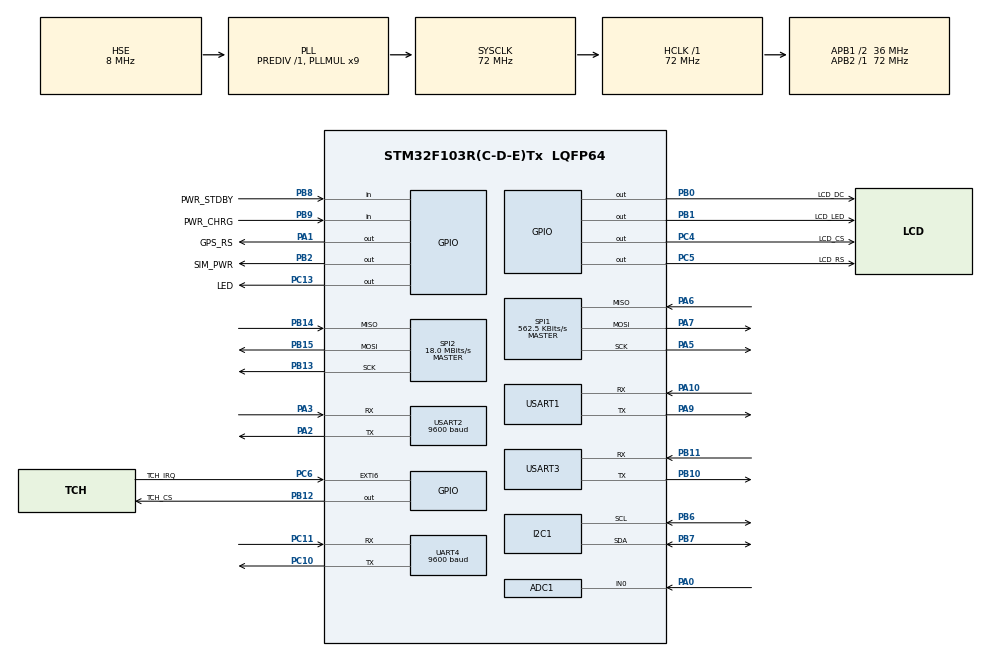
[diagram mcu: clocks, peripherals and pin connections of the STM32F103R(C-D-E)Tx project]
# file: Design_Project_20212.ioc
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ADC1.Channel-0\#ChannelRegularConversion=ADC_CHANNEL_0
ADC1.NbrOfConversionFlag=1
ADC1.Rank-0\#ChannelRegularConversion=1
ADC1.SamplingTime-0\#ChannelRegularConversion=ADC_SAMPLETIME_239CYCLES_5
ADC1.master=1
Dma.ADC1.0.Direction=DMA_PERIPH_TO_MEMORY
Dma.ADC1.0.Instance=DMA1_Channel1
Dma.ADC1.0.MemDataAlignment=DMA_MDATAALIGN_HALFWORD
Dma.ADC1.0.MemInc=DMA_MINC_ENABLE
Dma.ADC1.0.Mode=DMA_CIRCULAR
Dma.ADC1.0.PeriphDataAlignment=DMA_PDATAALIGN_HALFWORD
Dma.ADC1.0.PeriphInc=DMA_PINC_DISABLE
Dma.ADC1.0.Priority=DMA_PRIORITY_LOW
Dma.Request0=ADC1
FREERTOS.Tasks01=LCD_Task,24,200,LCDTASK,Default,NULL,Dynamic,NULL,NULL;SIM_Task,24,220,SIMTASK,Default,NULL,Dynamic,NULL,NULL;SEN_Task,24,200,SENSOR_Task,Default,NULL,Dynamic,NULL,NULL
FREERTOS.Timers01=LCD_Timer,LCD_Timer_Callback,osTimerPeriodic,Default,NULL,Dynamic,NULL;Touch_Timer,Touch_Timer_Callback,osTimerPeriodic,Default,NULL,Dynamic,NULL;LCD_Sleep,LCD_Sleep_Callback,osTimerOnce,Default,NULL,Dynamic,NULL
FREERTOS.configCHECK_FOR_STACK_OVERFLOW=0
FREERTOS.configGENERATE_RUN_TIME_STATS=0
FREERTOS.configMINIMAL_STACK_SIZE=100
FREERTOS.configTIMER_TASK_STACK_DEPTH=150
IWDG.Prescaler=IWDG_PRESCALER_128
IWDG.Reload=2500
Mcu.Family=STM32F1
Mcu.Name=STM32F103R(C-D-E)Tx
Mcu.Package=LQFP64
NVIC.DMA1_Channel1_IRQn=true\:5\:0\:false\:false\:true\:true\:false\:true\:true
NVIC.EXTI9_5_IRQn=true\:5\:0\:false\:false\:true\:false\:true\:true\:true
NVIC.PriorityGroup=NVIC_PRIORITYGROUP_4
NVIC.TIM1_UP_IRQn=true\:15\:0\:false\:false\:true\:false\:false\:true\:true
NVIC.TimeBase=TIM1_UP_IRQn
NVIC.TimeBaseIP=TIM1
NVIC.UART4_IRQn=true\:5\:0\:false\:false\:true\:true\:true\:true\:true
NVIC.USART1_IRQn=true\:5\:0\:false\:false\:true\:true\:true\:true\:true
NVIC.USART2_IRQn=true\:5\:0\:false\:false\:true\:true\:true\:true\:true
NVIC.USART3_IRQn=true\:5\:0\:false\:false\:true\:true\:true\:true\:true
PA0-WKUP.Signal=ADCx_IN0
PA1.GPIO_Label=GPS_RS
PA1.Signal=GPIO_Output
PA10.Mode=Asynchronous
PA10.Signal=USART1_RX
PA13.Mode=Serial_Wire
PA13.Signal=SYS_JTMS-SWDIO
PA14.Mode=Serial_Wire
PA14.Signal=SYS_JTCK-SWCLK
PA2.Mode=Asynchronous
PA2.Signal=USART2_TX
PA3.Mode=Asynchronous
PA3.Signal=USART2_RX
PA5.Mode=Full_Duplex_Master
PA5.Signal=SPI1_SCK
PA6.Mode=Full_Duplex_Master
PA6.Signal=SPI1_MISO
PA7.Mode=Full_Duplex_Master
PA7.Signal=SPI1_MOSI
PA9.Mode=Asynchronous
PA9.Signal=USART1_TX
PB0.GPIO_Label=LCD_DC
PB0.Signal=GPIO_Output
PB1.GPIO_Label=LCD_LED
PB1.Signal=GPIO_Output
PB10.Mode=Asynchronous
PB10.Signal=USART3_TX
PB11.Mode=Asynchronous
PB11.Signal=USART3_RX
PB12.GPIO_Label=TCH_CS
PB12.Signal=GPIO_Output
PB13.Mode=Full_Duplex_Master
PB13.Signal=SPI2_SCK
PB14.Mode=Full_Duplex_Master
PB14.Signal=SPI2_MISO
PB15.Mode=Full_Duplex_Master
PB15.Signal=SPI2_MOSI
PB2.GPIO_Label=SIM_PWR
PB2.Signal=GPIO_Output
PB6.Mode=I2C
PB6.Signal=I2C1_SCL
PB7.Mode=I2C
PB7.Signal=I2C1_SDA
PB8.GPIO_Label=PWR_STDBY
PB8.Signal=GPIO_Input
PB9.GPIO_Label=PWR_CHRG
PB9.Signal=GPIO_Input
PC10.Mode=Asynchronous
PC10.Signal=UART4_TX
PC11.Mode=Asynchronous
PC11.Signal=UART4_RX
PC13-TAMPER-RTC.GPIO_Label=LED
PC13-TAMPER-RTC.Signal=GPIO_Output
PC4.GPIO_Label=LCD_CS
PC4.Signal=GPIO_Output
PC5.GPIO_Label=LCD_RS
PC5.Signal=GPIO_Output
PC6.GPIO_Label=TCH_IRQ
PC6.GPIO_ModeDefaultEXTI=GPIO_MODE_IT_FALLING
PC6.GPIO_PuPd=GPIO_PULLUP
PC6.Signal=GPXTI6
PD0-OSC_IN.Mode=HSE-External-Oscillator
PD0-OSC_IN.Signal=RCC_OSC_IN
PD1-OSC_OUT.Mode=HSE-External-Oscillator
PD1-OSC_OUT.Signal=RCC_OSC_OUT
ProjectManager.HeapSize=0x200
ProjectManager.StackSize=0x400
ProjectManager.TargetToolchain=Makefile
RCC.ADCPresc=RCC_ADCPCLK2_DIV6
RCC.AHBFreq_Value=72000000
RCC.APB1CLKDivider=RCC_HCLK_DIV2
RCC.APB1Freq_Value=36000000
RCC.APB1TimFreq_Value=72000000
RCC.APB2Freq_Value=72000000
RCC.APB2TimFreq_Value=72000000
RCC.HCLKFreq_Value=72000000
RCC.PLLMUL=RCC_PLL_MUL9
RCC.PLLSourceVirtual=RCC_PLLSOURCE_HSE
RCC.SYSCLKFreq_VALUE=72000000
RCC.SYSCLKSource=RCC_SYSCLKSOURCE_PLLCLK
RCC.USBFreq_Value=72000000
SH.ADCx_IN0.0=ADC1_IN0,IN0
SPI1.BaudRatePrescaler=SPI_BAUDRATEPRESCALER_128
SPI1.CalculateBaudRate=562.5 KBits/s
SPI1.Direction=SPI_DIRECTION_2LINES
SPI1.Mode=SPI_MODE_MASTER
SPI1.VirtualType=VM_MASTER
SPI2.BaudRatePrescaler=SPI_BAUDRATEPRESCALER_2
SPI2.CalculateBaudRate=18.0 MBits/s
SPI2.Direction=SPI_DIRECTION_2LINES
SPI2.Mode=SPI_MODE_MASTER
SPI2.VirtualType=VM_MASTER
UART4.BaudRate=9600
UART4.VirtualMode=Asynchronous
USART1.VirtualMode=VM_ASYNC
USART2.BaudRate=9600
USART2.VirtualMode=VM_ASYNC
USART3.VirtualMode=VM_ASYNC
VP_FREERTOS_VS_CMSIS_V2.Mode=CMSIS_V2
VP_IWDG_VS_IWDG.Mode=IWDG_Activate
VP_SYS_VS_tim1.Mode=TIM1
board=custom

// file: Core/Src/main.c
/* USER CODE BEGIN Header */
/**
  ******************************************************************************
  * @file           : main.c
  * @brief          : Main program body
  ******************************************************************************
  * @attention
  *
  * Copyright (c) 2022 STMicroelectronics.
  * All rights reserved.
  *
  * This software is licensed under terms that can be found in the LICENSE file
  * in the root directory of this software component.
  * If no LICENSE file comes with this software, it is provided AS-IS.
  *
  ******************************************************************************
  */
/* USER CODE END Header */
#include "main.h"
#include "cmsis_os.h"
#include "adc.h"
#include "dma.h"
#include "i2c.h"
#include "iwdg.h"
#include "spi.h"
#include "usart.h"
#include "gpio.h"

void SystemClock_Config(void);
void MX_FREERTOS_Init(void);

int main(void)
{

  /* MCU Configuration--------------------------------------------------------*/

  /* Reset of all peripherals, Initializes the Flash interface and the Systick. */
  HAL_Init();

  /* Configure the system clock */
  SystemClock_Config();

  /* Initialize all configured peripherals */
  MX_GPIO_Init();
  MX_I2C1_Init();
  MX_SPI1_Init();
  MX_SPI2_Init();
  MX_UART4_Init();
  MX_USART1_UART_Init();
  MX_USART2_UART_Init();
  MX_DMA_Init();
  MX_ADC1_Init();
  MX_USART3_UART_Init();
  MX_IWDG_Init();

  /* Init scheduler */
  osKernelInitialize();  /* Call init function for freertos objects (in freertos.c) */
  MX_FREERTOS_Init();

  /* Start scheduler */
  osKernelStart();

  /* We should never get here as control is now taken by the scheduler */
  /* Infinite loop */
  while (1)
  {

  }
}

void SystemClock_Config(void)
{
  RCC_OscInitTypeDef RCC_OscInitStruct = {0};
  RCC_ClkInitTypeDef RCC_ClkInitStruct = {0};
  RCC_PeriphCLKInitTypeDef PeriphClkInit = {0};

  /** Initializes the RCC Oscillators according to the specified parameters
  * in the RCC_OscInitTypeDef structure.
  */
  RCC_OscInitStruct.OscillatorType = RCC_OSCILLATORTYPE_LSI|RCC_OSCILLATORTYPE_HSE;
  RCC_OscInitStruct.HSEState = RCC_HSE_ON;
  RCC_OscInitStruct.HSEPredivValue = RCC_HSE_PREDIV_DIV1;
  RCC_OscInitStruct.HSIState = RCC_HSI_ON;
  RCC_OscInitStruct.LSIState = RCC_LSI_ON;
  RCC_OscInitStruct.PLL.PLLState = RCC_PLL_ON;
  RCC_OscInitStruct.PLL.PLLSource = RCC_PLLSOURCE_HSE;
  RCC_OscInitStruct.PLL.PLLMUL = RCC_PLL_MUL9;
  if (HAL_RCC_OscConfig(&RCC_OscInitStruct) != HAL_OK)
  {
    Error_Handler();
  }

  /** Initializes the CPU, AHB and APB buses clocks
  */
  RCC_ClkInitStruct.ClockType = RCC_CLOCKTYPE_HCLK|RCC_CLOCKTYPE_SYSCLK
                              |RCC_CLOCKTYPE_PCLK1|RCC_CLOCKTYPE_PCLK2;
  RCC_ClkInitStruct.SYSCLKSource = RCC_SYSCLKSOURCE_PLLCLK;
  RCC_ClkInitStruct.AHBCLKDivider = RCC_SYSCLK_DIV1;
  RCC_ClkInitStruct.APB1CLKDivider = RCC_HCLK_DIV2;
  RCC_ClkInitStruct.APB2CLKDivider = RCC_HCLK_DIV1;

  if (HAL_RCC_ClockConfig(&RCC_ClkInitStruct, FLASH_LATENCY_2) != HAL_OK)
  {
    Error_Handler();
  }
  PeriphClkInit.PeriphClockSelection = RCC_PERIPHCLK_ADC;
  PeriphClkInit.AdcClockSelection = RCC_ADCPCLK2_DIV6;
  if (HAL_RCCEx_PeriphCLKConfig(&PeriphClkInit) != HAL_OK)
  {
    Error_Handler();
  }
}

void HAL_TIM_PeriodElapsedCallback(TIM_HandleTypeDef *htim)
{
  if (htim->Instance == TIM1) {
    HAL_IncTick();
  }
}

void Error_Handler(void)
{
  __disable_irq();
  while (1)
  {
  }
}

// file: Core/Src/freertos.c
/* USER CODE BEGIN Header */
/**
  ******************************************************************************
  * File Name          : freertos.c
  * Description        : Code for freertos applications
  ******************************************************************************
  * @attention
  *
  * Copyright (c) 2022 STMicroelectronics.
  * All rights reserved.
  *
  * This software is licensed under terms that can be found in the LICENSE file
  * in the root directory of this software component.
  * If no LICENSE file comes with this software, it is provided AS-IS.
  *
  ******************************************************************************
  */
/* USER CODE END Header */

#include "FreeRTOS.h"
#include "task.h"
#include "main.h"
#include "cmsis_os.h"

/* USER CODE BEGIN Includes */
#include "sim.h"
#include "l70.h"
#include "lcd.h"
#include "touch.h"
#include "mpu6050.h"
#include "ds1307.h"
#include "max30102.h"
#include "debug.h"
#include "stdlib.h"
#include "math.h"
#include "mqtt.h"
#include "DFPLAYER_MINI.h"
#include "timers.h"
#include "topic.h"

/* USER CODE END Includes */

/* USER CODE BEGIN PTD */
typedef enum
{
  STOP = 0,
  RUNNING = 1,
  PAUSE = 2
} Mode_t;

typedef struct
{
  uint16_t Voltage_12bits[1];
  float Voltage_V;
  float Voltage_Batt;
  uint8_t Perc_Batt;
  char cBatt[4];
} Battery_t;

/* USER CODE END PTD */

/* USER CODE BEGIN PD */

#define ADC_GAIN      (1.46527)
#define MAX_VOL       (4.22)
#define IR_THRESHOLD  (25000)

#define MAIN_PAGE     0
#define MP3_PAGE      1
#define DATA_PAGE_1   2
#define DATA_PAGE_2   3

#define ABS(x) ((x)<0 ? -(x) : (x))

/* USER CODE END PD */

/* USER CODE BEGIN Variables */
// extern IWDG_HandleTypeDef hiwdg;
extern I2C_HandleTypeDef hi2c1;
extern ADC_HandleTypeDef hadc1;
extern IWDG_HandleTypeDef hiwdg;

extern bool isNaize;

static bool isSystemOK = true;

static Mode_t DeviceState = STOP;
static MQTT_ST_t MQTT_Status = {
    .SIM_ST = SIM_SIMCARD_NOK,
    .MQTT_ST = MQTT_NOK
};
static bool isNewTime = false;
static bool isDeviceStateChange = false;

extern MQTT_t MQTT;
static char *GPSResponse;
static char latData[16] = "22.992335";
static char longData[16] = "105.886839";

static MPU6050_t MPU6050;
static RTC_t myRTC;
static max30102_t MAX30102 = {
  .Peak.maxPeak = 7,
  .Peak.minGap = 40
};
static uint8_t HeartRate = 0;
static uint32_t Step = 0;
static uint8_t TimeRun = 0;
static uint32_t IR_Value[250] = {0};
static uint8_t IR_Count = 0;
static uint32_t RD_Value[250] = {0};
static uint8_t RD_Count = 0;
static uint8_t count = 0;
static uint8_t tHR[4] = {0};
static bool isDataValid = false;

static Battery_t Batt = {
  .Perc_Batt = 0,
  .Voltage_12bits[0] = 0,
  .Voltage_Batt = 0.0,
  .Voltage_V = 0.0,
  .cBatt = {0}
};

static uint8_t CurrentPage = MAIN_PAGE;
static volatile bool isTouch = false;
static volatile bool isSleep = false;
const static myButton_t toPageLeft = {
  .pos_x = 30,
  .pos_y = 208,
  .color = ILI9341_LIGHTBLUE,
  .shape_r = 28
};
const static myButton_t toPageRight = {
  .pos_x = 290,
  .pos_y = 208,
  .color = ILI9341_LIGHTBLUE,
  .shape_r = 28
};
const static myButton_t bStart = {
  .pos_x = 130,
  .pos_y = 193,
  .color = ILI9341_GRAYBLUE,
  .shape_w = 60,
  .shape_h = 30
};
const static myButton_t bPause = {
  .pos_x = 90,
  .pos_y = 193,
  .color = ILI9341_GRAYBLUE,
  .shape_w = 60,
  .shape_h = 30
};
const static myButton_t bStop = {
  .pos_x = 170,
  .pos_y = 193,
  .color = ILI9341_GRAYBLUE,
  .shape_w = 60,
  .shape_h = 30
};
const static myButton_t bPlay = {
  .pos_x = 160,
  .pos_y = 120,
  .color = ILI9341_WHITE,
  .shape_r = 35
};
const static myButton_t bPrev = {
  .pos_x = 70,
  .pos_y = 120,
  .color = ILI9341_WHITE,
  .shape_r = 28
};
const static myButton_t bNext = {
  .pos_x = 250,
  .pos_y = 120,
  .color = ILI9341_WHITE,
  .shape_r = 28
};
const static myButton_t incVol = {
  .pos_x = 210,
  .pos_y = 190,
  .color = ILI9341_WHITE,
  .shape_r = 22
};
const static myButton_t decVol = {
  .pos_x = 110,
  .pos_y = 190,
  .color = ILI9341_WHITE,
  .shape_r = 22
};
static char DateFormat[22] = {0};
static char TimeFormat[8] = {0};
static char HRFormat[4] = {0};
static char StepFormat[7] = {0};
static char TimeRunFormat[5] = {0};
static bool isButtonChange = false;

static bool isMP3Playing = false;
static uint8_t MP3Volume = 1;

static uint8_t HRDataPlot[200] = {0};
static uint8_t HRDataIndex = 0;
static uint32_t StepDataPlot[200] = {0};
static uint8_t StepDataIndex = 0;

/* USER CODE END Variables */
/* Definitions for LCD_Task */
osThreadId_t LCD_TaskHandle;
const osThreadAttr_t LCD_Task_attributes = {
  .name = "LCD_Task",
  .stack_size = 512 * 4,
  .priority = (osPriority_t) osPriorityNormal,
};
/* Definitions for SIM_Task */
osThreadId_t SIM_TaskHandle;
const osThreadAttr_t SIM_Task_attributes = {
  .name = "SIM_Task",
  .stack_size = 512 * 4,
  .priority = (osPriority_t) osPriorityNormal,
};
/* Definitions for SEN_Task */
osThreadId_t SEN_TaskHandle;
const osThreadAttr_t SEN_Task_attributes = {
  .name = "SEN_Task",
  .stack_size = 512 * 4,
  .priority = (osPriority_t) osPriorityNormal,
};
/* Definitions for LCD_Timer */
osTimerId_t LCD_TimerHandle;
const osTimerAttr_t LCD_Timer_attributes = {
  .name = "LCD_Timer"
};
/* Definitions for Touch_Timer */
osTimerId_t Touch_TimerHandle;
const osTimerAttr_t Touch_Timer_attributes = {
  .name = "Touch_Timer"
};
/* Definitions for LCD_Sleep */
osTimerId_t LCD_SleepHandle;
const osTimerAttr_t LCD_Sleep_attributes = {
  .name = "LCD_Sleep"
};

/* USER CODE BEGIN FunctionPrototypes */

bool Connect_MQTT(void);
void updateParameter(uint8_t page);
void handleTouch(uint16_t x, uint16_t y, uint8_t page);
void updateButton(uint8_t page);

bool isPeak(int8_t* buffer, uint8_t size, uint8_t bandWith, int8_t minHeight, uint8_t numFlatPeak);

void Main_page(void);
void Mp3_page(void);
void Graph_page_1(void);
void Graph_page_2(void);

/* USER CODE END FunctionPrototypes */

void LCDTASK(void *argument);
void SIMTASK(void *argument);
void SENSOR_Task(void *argument);
void LCD_Timer_Callback(void *argument);
void Touch_Timer_Callback(void *argument);
void LCD_Sleep_Callback(void *argument);

void MX_FREERTOS_Init(void); /* (MISRA C 2004 rule 8.1) */

void MX_FREERTOS_Init(void) {

  /* Create the timer(s) */
  /* creation of LCD_Timer */
  LCD_TimerHandle = osTimerNew(LCD_Timer_Callback, osTimerPeriodic, NULL, &LCD_Timer_attributes);

  /* creation of Touch_Timer */
  Touch_TimerHandle = osTimerNew(Touch_Timer_Callback, osTimerPeriodic, NULL, &Touch_Timer_attributes);

  /* creation of LCD_Sleep */
  LCD_SleepHandle = osTimerNew(LCD_Sleep_Callback, osTimerOnce, NULL, &LCD_Sleep_attributes);

  /* Create the thread(s) */
  /* creation of LCD_Task */
  LCD_TaskHandle = osThreadNew(LCDTASK, NULL, &LCD_Task_attributes);

  /* creation of SIM_Task */
  SIM_TaskHandle = osThreadNew(SIMTASK, NULL, &SIM_Task_attributes);

  /* creation of SEN_Task */
  SEN_TaskHandle = osThreadNew(SENSOR_Task, NULL, &SEN_Task_attributes);

}

void LCDTASK(void *argument)
{
  /* USER CODE BEGIN LCDTASK */
  uint32_t TimeRefresh = HAL_GetTick();

  HAL_GPIO_WritePin(LED_GPIO_Port, LED_Pin, GPIO_PIN_RESET);

  ILI9341_Unselect();
  ILI9341_TouchUnselect();
  ILI9341_Init();
  isTouch = false;

  do
  {
    ds1307_get_current_date(&myRTC.Date);
    ds1307_get_current_time(&myRTC.Time);
  }
  while (myRTC.Time.minutes >= 60);

  ILI9341_FillRectangle(0, 0, 320, 25, ILI9341_BLACK);
  ILI9341_WriteString(10, 10, "SIM: ", Font_7x10, ILI9341_WHITE, ILI9341_BLACK);
  ILI9341_WriteString(80, 10, "GPRS: ", Font_7x10, ILI9341_WHITE, ILI9341_BLACK);
  ILI9341_WriteString(150, 10, "MQTT: ", Font_7x10, ILI9341_WHITE, ILI9341_BLACK);
  ILI9341_WriteString(225, 10, "Battery: ", Font_7x10, ILI9341_WHITE, ILI9341_BLACK);

  Main_page();

  uint16_t x = 0;
  uint16_t y = 0;

  TimeRefresh = HAL_GetTick();
  osTimerStart(LCD_TimerHandle, 5000);
  osTimerStart(Touch_TimerHandle, 50);
  osTimerStart(LCD_SleepHandle, 120000);
  if (isSystemOK == true)
  {
    HAL_IWDG_Refresh(&hiwdg);
  }
  // osThreadSuspend(LCD_TaskHandle);
  /* Infinite loop */
  for(;;)
  {
    if (isSystemOK == true)
    {
      HAL_IWDG_Refresh(&hiwdg);
    }
    osDelay(1);
    if ((HAL_GPIO_ReadPin(TCH_IRQ_GPIO_Port, TCH_IRQ_Pin) == GPIO_PIN_RESET) && (isTouch == true))
    {
      osDelay(100);
      if (HAL_GPIO_ReadPin(TCH_IRQ_GPIO_Port, TCH_IRQ_Pin) == GPIO_PIN_RESET)
      {
        x = 0;
        y = 0;
        while(ILI9341_TouchGetCoordinates(&y, &x) != true);
        y = 240 - y;
        x = 320 - x;
      }
      logPC("Touch Coordinate: (%i,%i)\n", x, y);
      xTimerReset(LCD_SleepHandle, 100);
      if (isSleep == true)
      {
        logPC("LCD awake!\n");
        updateParameter(CurrentPage);
        ILI9341_LCD_LED(true);
        // osTimerStart(LCD_TimerHandle, 5000);
        isSleep = false;
      }
      else
      {
        uint8_t Prev = CurrentPage;
        handleTouch(x, y, CurrentPage);
        if (Prev != CurrentPage)
        {
          if (CurrentPage == MAIN_PAGE)
          {
            Main_page();
          }
          else if (CurrentPage == MP3_PAGE)
          {
            Mp3_page();
          }
          else if (CurrentPage == DATA_PAGE_1)
          {
            Graph_page_1();
          }
          else if (CurrentPage == DATA_PAGE_2)
          {
            Graph_page_2();
          }
        }
        else
        {
          updateButton(CurrentPage);
        }
      }
      // ILI9341_DrawPixel(x, y, ILI9341_WHITE);
      osDelay(200);
    }
    else
    {
      updateParameter(CurrentPage);
    }
    isTouch = false;
    osThreadSuspend(LCD_TaskHandle);
  }
  /* USER CODE END LCDTASK */
}

void SIMTASK(void *argument)
{
  /* USER CODE BEGIN SIMTASK */
  SIM_Deinit();
  osThreadSuspend(SIM_TaskHandle);
  // osDelay(2000);
  uint32_t timeSIM = HAL_GetTick();
  uint32_t timePUB = HAL_GetTick();

  while ((SIM_Init() != true) && ((HAL_GetTick() - timeSIM) <= 20000))
  {
    osDelay(1000);
  }

  DF_Init(INIT_VOL);

  MQTT_Status.SIM_ST = SIM_SIMCARD_NOK;

  if (Connect_MQTT() == true)
  {
    osDelay(2000);
    // MQTT_Pub(STATUS_TOPIC, "1");
    // osDelay(1000);
    // MQTT_Sub(PING_TOPIC);
    osDelay(1000);
    MQTT_Sub(TIME_TOPIC);
  }

  osDelay(500);

  HAL_GPIO_WritePin(LED_GPIO_Port, LED_Pin, GPIO_PIN_SET);

  // l70_init();

  // DF_Sleep();

  // osTimerStart(MQTT_TimerHandle, 30000);
  timePUB = HAL_GetTick();
  uint32_t timeMP3 = HAL_GetTick();
  uint8_t ErrorTime = 0;

  /* Infinite loop */
  for(;;)
  {

    osDelay(100);
    // HAL_GPIO_TogglePin(LED_GPIO_Port, LED_Pin);
    if (((HAL_GetTick() - timeSIM) >= 90000) && (MQTT.mqttServer.connect == 1))
    {
      if (MQTT_PingReq() != true)
      {
        MQTT_Status.MQTT_ST = MQTT_NOK;
        MQTT.mqttServer.connect = 0;
        ErrorTime++;
      }
      else
      {
        MQTT.mqttServer.connect = 1;
        MQTT_Status.MQTT_ST = MQTT_OK;
        ErrorTime = 0;
      }
      timeSIM = HAL_GetTick();
    }
    if ((MQTT_Status.MQTT_ST != MQTT_OK) || (MQTT.mqttServer.connect == 0) || (MQTT_Status.SIM_ST != SIM_GPRS_OK))
    {
      if (Connect_MQTT() == true)
      {
        // osDelay(1000);
        // MQTT_Sub(PING_TOPIC);
        osDelay(1000);
        MQTT_Sub(TIME_TOPIC);
        ErrorTime = 0;
        timeSIM = HAL_GetTick();
      }
      else
      {ErrorTime++;}
    }
    if (MQTT.mqttReceive.newEvent == 1)
    {
      HAL_GPIO_TogglePin(LED_GPIO_Port, LED_Pin);
      logPC("MQTT Received from topic \"%s\", message is \"%s\"\n", MQTT.mqttReceive.topic, MQTT.mqttReceive.payload);
      MQTT.mqttReceive.newEvent = 0;
      SIM_clearRX();
      if (strstr(MQTT.mqttReceive.topic, "time") != NULL)
      {
        char* token = strtok(MQTT.mqttReceive.payload, ",");
        myRTC.Date.year = atoi(token);
        token = strtok(NULL, ",");
        myRTC.Date.month = atoi(token);
        token = strtok(NULL, ",");
        myRTC.Date.day = atoi(token);
        token = strtok(NULL, ",");
        myRTC.Date.date = atoi(token);
        token = strtok(NULL, ",");
        myRTC.Time.hours = atoi(token);
        token = strtok(NULL, ",");
        myRTC.Time.minutes = atoi(token);
        token = strtok(NULL, ",");
        myRTC.Time.seconds = atoi(token);
        isNewTime = true;
      }
      HAL_GPIO_TogglePin(LED_GPIO_Port, LED_Pin);
      timeSIM = HAL_GetTick();
    }
    if ((DeviceState == RUNNING) && ((HAL_GetTick() - timePUB) >= 10000) && (MQTT_Status.MQTT_ST == MQTT_OK))
    {
      char Upload[100] = {0};
      sprintf(Upload, "{\"HeartRate\":%03d,\"Step\":%06d,\"Period\":%03d,\"Lat\":%s,\"Lon\":%s}", HeartRate, Step, TimeRun, latData, longData);
      logPC("Data packet is %s\n", Upload);
      MQTT_Pub(DATA_TOPIC, Upload);
      timeSIM = HAL_GetTick();
      timePUB = HAL_GetTick();
    }
    else if ((DeviceState == STOP) || (DeviceState == PAUSE))
    {
      timePUB = HAL_GetTick();
    }
    if (DF_getState() == PAUSING && isMP3Playing == true)
    {
      osDelay(100);
      DF_Next();
      DF_Playback();
    }
    if (ErrorTime >= 5)
    {
      ErrorTime = 5;
      SIM_Deinit();
      osDelay(2000);
      SIM_Init();
      MQTT_Status.SIM_ST = SIM_SIMCARD_NOK;
      MQTT_Status.MQTT_ST = MQTT_NOK;
    }
    if ((isDeviceStateChange == true) && (MQTT_Status.MQTT_ST == MQTT_OK))
    {
      if (DeviceState == RUNNING)
      {MQTT_Pub(STATUS_TOPIC, "1");}
      else
      {MQTT_Pub(STATUS_TOPIC, "0");}
      osDelay(500);
      isDeviceStateChange = false;
    }
    if ((DF_getTotalSongs() == 0) && ((HAL_GetTick() - timeMP3) >= 10000))
    {
      DF_Init(INIT_VOL);
      osDelay(100);
      timeMP3 = HAL_GetTick();
    }
  }
  /* USER CODE END SIMTASK */
}

void SENSOR_Task(void *argument)
{
  /* USER CODE BEGIN SENSOR_Task */
  uint32_t lastTime = HAL_GetTick();
  uint32_t TimeHR = HAL_GetTick();
  uint32_t getTime = HAL_GetTick();
  uint32_t runTick = HAL_GetTick();

  Debug_Init();

  while (MPU6050_Init(&hi2c1) && ((HAL_GetTick() - lastTime) <= 10000))
  {
    osDelay(50);
  }
  if ((HAL_GetTick() - lastTime) > 10000)
  {
    // logPC("MPU6050 FAILED!\n");
    isSystemOK = false;
  }
  else
  {
    // logPC("MPU6050 OK\n");
  }

  osDelay(50);

  max30102_init(&MAX30102, &hi2c1);
  max30102_reset(&MAX30102);
  max30102_clear_fifo(&MAX30102);
  max30102_set_fifo_config(&MAX30102, max30102_smp_ave_32, 1, 5);

  // Sensor settings
  max30102_set_led_pulse_width(&MAX30102, max30102_pw_16_bit);
  max30102_set_adc_resolution(&MAX30102, max30102_adc_2048);
  max30102_set_sampling_rate(&MAX30102, max30102_sr_800);
  max30102_set_led_current_1(&MAX30102, 6.5);
  max30102_set_led_current_2(&MAX30102, 6.5);

  // Enter SpO2 mode
  max30102_set_mode(&MAX30102, max30102_spo2);
  max30102_set_a_full(&MAX30102, 0);

  // Initiate 1 temperature measurement
  max30102_set_die_temp_en(&MAX30102, 0);
  max30102_set_die_temp_rdy(&MAX30102, 0);

  uint8_t en_reg[2] = {0};
  max30102_read(&MAX30102, 0x00, en_reg, 1);
  osDelay(100);

  MAX30102.Peak.nPeak = 0;
  memset(MAX30102.Peak.peakLoc, '\0', sizeof(MAX30102.Peak.peakLoc));
  memset(tHR, '\0', sizeof(tHR));
  lastTime = HAL_GetTick();
  TimeHR = HAL_GetTick();
  getTime = HAL_GetTick();
  runTick = HAL_GetTick();

  int8_t AngleBuf[30] = {0};
  uint8_t fromLastPeak = 0;
  uint8_t startup = 0;

  // osDelay(500);
  /* Infinite loop */
  for(;;)
  {
    if ((HAL_GetTick() - getTime) >= 5000)
    {
      ds1307_get_current_date(&myRTC.Date);
      ds1307_get_current_time(&myRTC.Time);
      Batt.Voltage_V =  ((float) Batt.Voltage_12bits[0] / 4095) * 3.3;
      Batt.Voltage_Batt = Batt.Voltage_V * ADC_GAIN;
      Batt.Perc_Batt = (uint8_t) (Batt.Voltage_Batt * 100 / MAX_VOL);
      HAL_ADC_Start_DMA(&hadc1, (uint32_t*)Batt.Voltage_12bits, 1);
      if (myRTC.Date.year == 8)
      {
        MPU6050_Init(&hi2c1);
      }
      getTime = HAL_GetTick();
    }

    if (isNewTime == true)
    {
      ds1307_set_current_date(&myRTC.Date);
      ds1307_set_current_time(&myRTC.Time);
      isNewTime = false;
    }

    if ((HAL_GetTick() - lastTime) >= 30000)
    {
      char buf[5] = {0};
      // logPC("HELLO! Now is %02d/%02d/%02d %02d:%02d:%02d\n", myRTC.Date.date, myRTC.Date.month, myRTC.Date.year, myRTC.Time.hours, myRTC.Time.minutes, myRTC.Time.seconds);
      // logPC("ADC 12-bit value is %hu\n", Batt.Voltage_12bits[0]);
      // ftoa(Batt.Voltage_V, buf, 2);
      // logPC("ADC Voltage is %s\n", buf);
      // memset(buf, '\0', sizeof(buf));
      // ftoa0(Batt.Voltage_Batt, buf, 2);
      // logPC("Batt Voltage is %s\n", buf);
      // logPC("Percent Battery is %hd\n", Batt.Perc_Batt);
      lastTime = HAL_GetTick();
    }

    if ((HAL_GetTick() - TimeHR) >= 15000)
    {
      HeartRate = 0;
    }

    if (DeviceState == RUNNING)
    {
      if ((HAL_GetTick() - runTick) >= 60000)
      {
        TimeRun++;
        runTick = HAL_GetTick();
      }

      //--------------------------------------------------------------------- MPU -------------------------------------------------------------------

      MPU6050_Read_All(&hi2c1, &MPU6050);
      if ((MPU6050.Ax == 0.0) || (MPU6050.Ay == 0.0) || (MPU6050.Az == 0.0))
      {
        MPU6050_Init(&hi2c1);
        osDelay(100);
        MPU6050_Read_All(&hi2c1, &MPU6050);
      }

#if PLOT == 1
      // logPC("$%i %i %i;", (int)MPU6050.KalmanAngleX, (int)MPU6050.KalmanAngleY, (int)MPU6050.KalmanAngleZ);
#endif

      if (MPU6050.KalmanAngleZ != 0.0)
      {
        for (uint8_t i = 0; i < sizeof(AngleBuf)-1; i++)
        {
          AngleBuf[i] = AngleBuf[i+1];
        }
        AngleBuf[29] = (int8_t)MPU6050.KalmanAngleZ;
      }

      if (startup < 30)
      {
        startup++;
      }

      if ((fromLastPeak >= 7) && (startup >= 30))
      {
        if (isPeak(AngleBuf, sizeof(AngleBuf), 14, 15, 4) == true)
        {
          Step++;
          fromLastPeak = 0;
          if (osThreadGetState(LCD_TaskHandle) == osThreadBlocked)
          {
            osThreadResume(LCD_TaskHandle);
          }
        }
        else if (fromLastPeak < 250)
        {
          fromLastPeak++;
        }
      }
      else if (fromLastPeak < 250)
      {
        fromLastPeak++;
      }

      //--------------------------------------------------------------------- MAX -------------------------------------------------------------------

      max30102_read_fifo(&MAX30102);

      count = 0;
      while (MAX30102._ir_samples[count] != '\0')
      {
        IR_Value[IR_Count++] = MAX30102._ir_samples[count];
        RD_Value[RD_Count++] = MAX30102._red_samples[count];
        count++;
      }

      if (IR_Count >= 200)
      {
        isDataValid = true;
        for (uint8_t i = 0; ((i < 200) && (isDataValid == true)); i++)
        {
          // if (IR_Value[i] < IR_THRESHOLD*5)
          // {
          //   isDataValid = false;
          //   // logPC("Finger OFF\n");
          //   if (isNaize == true)
          //   {
          //     HeartRate += (int8_t) random_number(-5, 5);
          //     if (HeartRate >= 105)
          //     {HeartRate = 105;}
          //     if (HeartRate <= 75)
          //     {HeartRate = 75;}
          //     TimeHR = HAL_GetTick();
          //   }
          // }
          // else
          {
            // if ((i >= 2) && (i <= 197))
            // {
            //   IR_Value[i-1] = (IR_Value[i-2] + IR_Value[i-1] + IR_Value[i]) / 3;
            //   IR_Value[i] = (IR_Value[i-2] + IR_Value[i-1] + IR_Value[i] + IR_Value[i+1] + IR_Value[i+2]) / 5;
            //   IR_Value[i+1] = (IR_Value[i+2] + IR_Value[i+1] + IR_Value[i]) / 3;
            // }
#if PLOT == 1
            // char t[8] = {0};
            // t[0] = 0xAA;
            // t[1] = 0xBB;
            // t[2] = 0x04;
            // t[3] = (uint8_t)(((uint32_t)(IR_Value[i]/5) >> 24U) & 0xFF);
            // t[4] = (uint8_t)(((uint32_t)(IR_Value[i]/5) >> 16U) & 0xFF);
            // t[5] = (uint8_t)(((uint32_t)(IR_Value[i]/5) >> 8U) & 0xFF);
            // t[6] = (uint8_t)(((uint32_t)(IR_Value[i]/5) >> 0U) & 0xFF);
            // logPC("%s", t);
            logPC("%i,%i\n", IR_Value[i]/5, RD_Value[i]/5);
#endif
          }
        }
        if (isDataValid == true)
        {
          // logPC("Finger ON\n");
          MAX30102.Peak.nPeak = 0;
          for (uint8_t i = 0; i < 10; i++)
          {
            MAX30102.Peak.peakLoc[i] = '\0';
          }

          maxim_find_peaks(&MAX30102, IR_Value, (uint8_t)200);

          if (MAX30102.Peak.nPeak > 1)
          {
            uint32_t gap = 1;
            for (uint8_t i = 0; i < (MAX30102.Peak.nPeak-1); i++)
            {
              gap += (MAX30102.Peak.peakLoc[i+1] - MAX30102.Peak.peakLoc[i]);
            }

            uint8_t tHeartRate = (uint8_t)((60000.0 * MAX30102.Peak.nPeak) / (gap * (MAX30102.deltaTSample*2)));
            if ((tHeartRate >= 55) && (tHeartRate <= 140))
            {
              TimeHR = HAL_GetTick();
              tHR[0] = tHR[1];
              tHR[1] = tHR[2];
              tHR[2] = tHR[3];
              tHR[3] = tHeartRate;
              if (tHR[0] != '\0')
              {
                HeartRate = (uint8_t)((tHR[0] + tHR[1] + tHR[2] + tHR[3]) / 4);
                // logPC("Heart Rate: %d BPM\n", HeartRate);
              }
            }
          }
        }
        memset(IR_Value, '\0', 200*4);
        memcpy(IR_Value, IR_Value+200, 50*4);
        IR_Count -= 200;
      }
    }
    else
    {
      runTick = HAL_GetTick();
    }
    osDelay(50);
  }
  /* USER CODE END SENSOR_Task */
}

/* LCD_Timer_Callback function */
void LCD_Timer_Callback(void *argument)
{
  /* USER CODE BEGIN LCD_Timer_Callback */
  if (isSleep != true)
  {
    if (osThreadGetState(LCD_TaskHandle) == osThreadBlocked)
    {
      osThreadResume(LCD_TaskHandle);
    }
  }
  else
  {
    if (isSystemOK == true)
    {
      HAL_IWDG_Refresh(&hiwdg);
    }
  }

  if (DeviceState == RUNNING)
  {
    if (HRDataIndex >= 200)
    {
      for (uint8_t i = 0; i < 199; i++)
      {
        HRDataPlot[i] = HRDataPlot[i+1];
      }
      HRDataPlot[199] = HeartRate;
    }
    else
    {HRDataPlot[HRDataIndex++] = HeartRate;}

    if (StepDataIndex >= 200)
    {
      for (uint8_t i = 0; i < 199; i++)
      {
        StepDataPlot[i] = StepDataPlot[i+1];
      }
      StepDataPlot[199] = Step;
    }
    else
    {StepDataPlot[StepDataIndex++] = Step;}

    // if (isNaize == true)
    // {Step += (uint8_t) random_number(5, 20);}
  }
  /* USER CODE END LCD_Timer_Callback */
}

/* Touch_Timer_Callback function */
void Touch_Timer_Callback(void *argument)
{
  /* USER CODE BEGIN Touch_Timer_Callback */
  if ((isTouch == true) && (osThreadGetState(LCD_TaskHandle) == osThreadBlocked))
  {
    osThreadResume(LCD_TaskHandle);
  }
  /* USER CODE END Touch_Timer_Callback */
}

/* LCD_Sleep_Callback function */
void LCD_Sleep_Callback(void *argument)
{
  /* USER CODE BEGIN LCD_Sleep_Callback */
  logPC("LCD asleep!\n");
  ILI9341_LCD_LED(false);
  // osTimerStop(LCD_TimerHandle);
  isSleep = true;
  /* USER CODE END LCD_Sleep_Callback */
}

/* USER CODE BEGIN Application */
void HAL_UART_RxCpltCallback(UART_HandleTypeDef *huart)
{
  if (huart->Instance == USART3)
  {
    SIM_RXCallback();
  }
  if (huart->Instance == USART2)
  {
    l70_callback();
  }
  if (huart->Instance == USART1)
  {
    debug_callback();
  }
  if (huart->Instance == UART4)
  {
    DF_RX_Callback();
  }
}

void HAL_GPIO_EXTI_Callback(uint16_t GPIO_Pin)
{
  if ((GPIO_Pin == TCH_IRQ_Pin) && (isTouch != true))
  {
    isTouch = true;
    // osSemaphoreRelease(LCD_TouchHandle);
  }
}

//============================================================================================================================

bool Connect_MQTT(void)
{
  uint32_t TIMEOUT = HAL_GetTick();
  if (MQTT_Status.SIM_ST == SIM_SIMCARD_NOK)
  {
    TIMEOUT = HAL_GetTick();
    while ((SIM_checkSIMCard() != true) && ((HAL_GetTick() - TIMEOUT) <= 15000))
    {
      osDelay(1000);
    }

    if ((HAL_GetTick() - TIMEOUT) <= 10000)
    {
      MQTT_Status.SIM_ST = SIM_SIMCARD_OK;
      logPC("SIM OK\n");
      osDelay(1000);
    }
    else
    {
      logPC("SIM FAIL\n");
      return false;
    }
  }

  if ((MQTT_Status.SIM_ST == SIM_SIMCARD_OK) || (MQTT_Status.SIM_ST == SIM_GPRS_NOK))
  {
    if (SIM_startGPRS() == true)
    {
      logPC("GPRS OK\n");
      MQTT_Status.SIM_ST = SIM_GPRS_OK;
      osDelay(1000);
    }
    else
    {
      logPC("GPRS FAIL\n");
      MQTT_Status.SIM_ST = SIM_GPRS_NOK;
      return false;
    }

  }

  if (MQTT_Status.SIM_ST == SIM_GPRS_OK)
  {
    MQTT.mqttServer.host = "test.mosquitto.org";
    MQTT.mqttServer.port = 1883;
    MQTT.mqttClient.username = "";
    MQTT.mqttClient.clientID = "hmmm";
    MQTT.mqttClient.pass = "";
    MQTT.mqttClient.keepAliveInterval = 120;

    MQTT_Connect();

    osDelay(1000);

    if (MQTT.mqttServer.connect == 1)
    {
      logPC("MQTT OK\n");
      MQTT_Status.MQTT_ST = MQTT_OK;
      return true;
    }
    else
    {
      logPC("MQTT FAIL\n");
      MQTT_Status.MQTT_ST = MQTT_NOK;
      return false;
    }
  }

  return false;
}

void updateParameter(uint8_t page)
{
  switch (CurrentPage)
  {
    case MAIN_PAGE:
    {
      if ((MQTT_Status.SIM_ST == SIM_SIMCARD_OK) || (MQTT_Status.SIM_ST == SIM_GPRS_OK))
      {ILI9341_WriteString(45, 10, "OK ", Font_7x10, ILI9341_GREEN, ILI9341_BLACK);}
      else
      {ILI9341_WriteString(45, 10, "nOK", Font_7x10, ILI9341_RED, ILI9341_BLACK);}
      if (MQTT_Status.SIM_ST == SIM_GPRS_OK)
      {ILI9341_WriteString(122, 10, "OK ", Font_7x10, ILI9341_GREEN, ILI9341_BLACK);}
      else
      {ILI9341_WriteString(122, 10, "nOK", Font_7x10, ILI9341_RED, ILI9341_BLACK);}
      if ((MQTT_Status.MQTT_ST == MQTT_OK) && (MQTT_Status.SIM_ST == SIM_GPRS_OK))
      {ILI9341_WriteString(192, 10, "OK ", Font_7x10, ILI9341_GREEN, ILI9341_BLACK);}
      else
      {ILI9341_WriteString(192, 10, "nOK", Font_7x10, ILI9341_RED, ILI9341_BLACK);}

      ILI9341_WriteString(225, 10, "Battery: ", Font_7x10, ILI9341_WHITE, ILI9341_BLACK);
      intToStr(Batt.Perc_Batt, Batt.cBatt, 3);
      ILI9341_WriteString(288, 10, Batt.cBatt, Font_7x10, ILI9341_YELLOW, ILI9341_BLACK);
      ILI9341_WriteString(309, 10, "%", Font_7x10, ILI9341_WHITE, ILI9341_BLACK);

      memset(DateFormat, '\0', sizeof(DateFormat));
      sprintf(DateFormat, "~~~ %02d/%02d/%4d ~~~\0", myRTC.Date.date, myRTC.Date.month, myRTC.Date.year+2000);
      ILI9341_WriteString(97, 30, DateFormat, Font_7x10, ILI9341_WHITE, ILI9341_BLACK);

      memset(TimeFormat, '\0', sizeof(TimeFormat));
      sprintf(TimeFormat, "%02d:%02d\0", myRTC.Time.hours, myRTC.Time.minutes);
      ILI9341_WriteString(133, 45, TimeFormat, Font_11x18, ILI9341_CYAN, ILI9341_BLACK);

      memset(HRFormat, '\0', sizeof(HRFormat));
      sprintf(HRFormat, "%03d", HeartRate);
      ILI9341_WriteString(37, 95, HRFormat, Font_11x18, ILI9341_RED, ILI9341_BLACK);

      memset(StepFormat, '\0', sizeof(StepFormat));
      sprintf(StepFormat, "%06ld", Step);
      ILI9341_WriteString(177, 95, StepFormat, Font_11x18, ILI9341_ORANGE, ILI9341_BLACK);

      memset(TimeRunFormat, '\0', sizeof(TimeRunFormat));
      sprintf(TimeRunFormat, "%03d", TimeRun);
      ILI9341_WriteString(36, 150, TimeRunFormat, Font_11x18, ILI9341_PINK, ILI9341_BLACK);

      ILI9341_WriteString(229, 147, latData, Font_7x10, ILI9341_GREEN, ILI9341_BLACK);
      ILI9341_WriteString(222, 160, longData, Font_7x10, ILI9341_GREEN, ILI9341_BLACK);

      break;
    }
    case MP3_PAGE:
    {
      if ((MQTT_Status.SIM_ST == SIM_SIMCARD_OK) || (MQTT_Status.SIM_ST == SIM_GPRS_OK))
      {ILI9341_WriteString(45, 10, "OK ", Font_7x10, ILI9341_GREEN, ILI9341_BLACK);}
      else
      {ILI9341_WriteString(45, 10, "nOK", Font_7x10, ILI9341_RED, ILI9341_BLACK);}
      if (MQTT_Status.SIM_ST == SIM_GPRS_OK)
      {ILI9341_WriteString(122, 10, "OK ", Font_7x10, ILI9341_GREEN, ILI9341_BLACK);}
      else
      {ILI9341_WriteString(122, 10, "nOK", Font_7x10, ILI9341_RED, ILI9341_BLACK);}
      if ((MQTT_Status.MQTT_ST == MQTT_OK) && (MQTT_Status.SIM_ST == SIM_GPRS_OK))
      {ILI9341_WriteString(192, 10, "OK ", Font_7x10, ILI9341_GREEN, ILI9341_BLACK);}
      else
      {ILI9341_WriteString(192, 10, "nOK", Font_7x10, ILI9341_RED, ILI9341_BLACK);}

      ILI9341_WriteString(225, 10, "Battery: ", Font_7x10, ILI9341_WHITE, ILI9341_BLACK);
      intToStr(Batt.Perc_Batt, Batt.cBatt, 3);
      ILI9341_WriteString(288, 10, Batt.cBatt, Font_7x10, ILI9341_YELLOW, ILI9341_BLACK);
      ILI9341_WriteString(309, 10, "%", Font_7x10, ILI9341_WHITE, ILI9341_BLACK);
      // ILI9341_WriteString(200, 50, "VOLUME: ", Font_11x18, ILI9341_YELLOW, ILI9341_BLACK);
      char temp[5] = {0};
      intToStr0(MP3Volume, temp, 2);
      ILI9341_WriteString(288, 50, temp, Font_11x18, ILI9341_YELLOW, ILI9341_BLACK);

      // ILI9341_WriteString(10, 50, "TRACK: ", Font_11x18, ILI9341_CYAN, ILI9341_BLACK);
      memset(temp, '\0', sizeof(temp));
      intToStr0(DF_getCurrentSongNumber(), temp, 4);
      ILI9341_WriteString(87, 50, temp, Font_11x18, ILI9341_CYAN, ILI9341_BLACK);
      // ILI9341_WriteString(131, 50, "/", Font_11x18, ILI9341_CYAN, ILI9341_BLACK);
      memset(temp, '\0', sizeof(temp));
      intToStr0(DF_getTotalSongs(), temp, 4);
      ILI9341_WriteString(142, 50, temp, Font_11x18, ILI9341_CYAN, ILI9341_BLACK);
      break;
    }
    case DATA_PAGE_1:
    {
      if ((MQTT_Status.SIM_ST == SIM_SIMCARD_OK) || (MQTT_Status.SIM_ST == SIM_GPRS_OK))
      {ILI9341_WriteString(45, 10, "OK ", Font_7x10, ILI9341_GREEN, ILI9341_BLACK);}
      else
      {ILI9341_WriteString(45, 10, "nOK", Font_7x10, ILI9341_RED, ILI9341_BLACK);}
      if (MQTT_Status.SIM_ST == SIM_GPRS_OK)
      {ILI9341_WriteString(122, 10, "OK ", Font_7x10, ILI9341_GREEN, ILI9341_BLACK);}
      else
      {ILI9341_WriteString(122, 10, "nOK", Font_7x10, ILI9341_RED, ILI9341_BLACK);}
      if ((MQTT_Status.MQTT_ST == MQTT_OK) && (MQTT_Status.SIM_ST == SIM_GPRS_OK))
      {ILI9341_WriteString(192, 10, "OK ", Font_7x10, ILI9341_GREEN, ILI9341_BLACK);}
      else
      {ILI9341_WriteString(192, 10, "nOK", Font_7x10, ILI9341_RED, ILI9341_BLACK);}

      ILI9341_WriteString(225, 10, "Battery: ", Font_7x10, ILI9341_WHITE, ILI9341_BLACK);
      intToStr(Batt.Perc_Batt, Batt.cBatt, 3);
      ILI9341_WriteString(288, 10, Batt.cBatt, Font_7x10, ILI9341_YELLOW, ILI9341_BLACK);
      ILI9341_WriteString(309, 10, "%", Font_7x10, ILI9341_WHITE, ILI9341_BLACK);
      break;
    }
    case DATA_PAGE_2:
    {
      if ((MQTT_Status.SIM_ST == SIM_SIMCARD_OK) || (MQTT_Status.SIM_ST == SIM_GPRS_OK))
      {ILI9341_WriteString(45, 10, "OK ", Font_7x10, ILI9341_GREEN, ILI9341_BLACK);}
      else
      {ILI9341_WriteString(45, 10, "nOK", Font_7x10, ILI9341_RED, ILI9341_BLACK);}
      if (MQTT_Status.SIM_ST == SIM_GPRS_OK)
      {ILI9341_WriteString(122, 10, "OK ", Font_7x10, ILI9341_GREEN, ILI9341_BLACK);}
      else
      {ILI9341_WriteString(122, 10, "nOK", Font_7x10, ILI9341_RED, ILI9341_BLACK);}
      if ((MQTT_Status.MQTT_ST == MQTT_OK) && (MQTT_Status.SIM_ST == SIM_GPRS_OK))
      {ILI9341_WriteString(192, 10, "OK ", Font_7x10, ILI9341_GREEN, ILI9341_BLACK);}
      else
      {ILI9341_WriteString(192, 10, "nOK", Font_7x10, ILI9341_RED, ILI9341_BLACK);}

      ILI9341_WriteString(225, 10, "Battery: ", Font_7x10, ILI9341_WHITE, ILI9341_BLACK);
      intToStr(Batt.Perc_Batt, Batt.cBatt, 3);
      ILI9341_WriteString(288, 10, Batt.cBatt, Font_7x10, ILI9341_YELLOW, ILI9341_BLACK);
      ILI9341_WriteString(309, 10, "%", Font_7x10, ILI9341_WHITE, ILI9341_BLACK);
      break;
    }
    default:
    {
      break;
    }
  }
}

void updateButton(uint8_t page)
{
  if (page == MAIN_PAGE)
  {
    if (isButtonChange == true)
    {
      ILI9341_FillRectangle(bPause.pos_x, bPause.pos_y, 140, 30, ILI9341_BLACK);

      if (DeviceState == STOP)
      {
        ILI9341_FillRectangle(bStart.pos_x, bStart.pos_y, bStart.shape_w, bStart.shape_h, bStart.color);
        ILI9341_WriteString(bStart.pos_x+3, bStart.pos_y+6, "START", Font_11x18, ILI9341_WHITE, bStart.color);
      }
      else if (DeviceState == RUNNING)
      {
        ILI9341_FillRectangle(bPause.pos_x, bPause.pos_y, bPause.shape_w, bPause.shape_h, bPause.color);
        ILI9341_WriteString(bPause.pos_x+3, bPause.pos_y+6, "PAUSE", Font_11x18, ILI9341_WHITE, bPause.color);
        ILI9341_FillRectangle(bStop.pos_x, bStop.pos_y, bStop.shape_w, bStop.shape_h, bStop.color);
        ILI9341_WriteString(bStop.pos_x+8, bStop.pos_y+6, "STOP", Font_11x18, ILI9341_WHITE, bStop.color);
      }
      else
      {
        ILI9341_FillRectangle(bPause.pos_x, bPause.pos_y, bPause.shape_w, bPause.shape_h, bPause.color);
        ILI9341_WriteString(bPause.pos_x+3, bPause.pos_y+6, "START", Font_11x18, ILI9341_WHITE, bPause.color);
        ILI9341_FillRectangle(bStop.pos_x, bStop.pos_y, bStop.shape_w, bStop.shape_h, bStop.color);
        ILI9341_WriteString(bStop.pos_x+8, bStop.pos_y+6, "STOP", Font_11x18, ILI9341_WHITE, bStop.color);
      }
      isButtonChange = false;
    }
  }
  else if (page == MP3_PAGE)
  {
    if (isButtonChange == true)
    {
      ILI9341_FillCircle(bPlay.pos_x, bPlay.pos_y, bPlay.shape_r, bPlay.color);
      if (isMP3Playing == false)
      {ILI9341_FillTriangle(bPlay.pos_x+20, bPlay.pos_y, bPlay.pos_x-10, bPlay.pos_y+18, bPlay.pos_x-10, bPlay.pos_y-18, ILI9341_ORANGE);}
      else
      {
        ILI9341_FillRectangle(bPlay.pos_x-5-bPlay.shape_r+20, bPlay.pos_y-bPlay.shape_r/2, bPlay.shape_r-20, bPlay.shape_r, ILI9341_RED);
        ILI9341_FillRectangle(bPlay.pos_x+5, bPlay.pos_y-bPlay.shape_r/2, bPlay.shape_r-20, bPlay.shape_r, ILI9341_RED);
      }
      isButtonChange = false;
    }
    // ILI9341_WriteString(200, 50, "VOLUME: ", Font_11x18, ILI9341_YELLOW, ILI9341_BLACK);
    char temp[5] = {0};
    intToStr0(MP3Volume, temp, 2);
    ILI9341_WriteString(288, 50, temp, Font_11x18, ILI9341_YELLOW, ILI9341_BLACK);

    // ILI9341_WriteString(10, 50, "TRACK: ", Font_11x18, ILI9341_CYAN, ILI9341_BLACK);
    memset(temp, '\0', sizeof(temp));
    intToStr0(DF_getCurrentSongNumber(), temp, 4);
    ILI9341_WriteString(87, 50, temp, Font_11x18, ILI9341_CYAN, ILI9341_BLACK);
    // ILI9341_WriteString(131, 50, "/", Font_11x18, ILI9341_CYAN, ILI9341_BLACK);
    // memset(temp, '\0', sizeof(temp));
    // intToStr0(DF_getTotalSongs(), temp, 4);
    // ILI9341_WriteString(142, 50, temp, Font_11x18, ILI9341_CYAN, ILI9341_BLACK);
  }
}

void handleTouch(uint16_t x, uint16_t y, uint8_t page)
{
  switch (page)
  {
    case MAIN_PAGE:
    {
      if (ILI9341_checkButton(x, y, &toPageLeft))
      {
        CurrentPage = MP3_PAGE;
      }
      else if (ILI9341_checkButton(x, y, &toPageRight))
      {
        CurrentPage = DATA_PAGE_1;
      }
      else if (DeviceState == STOP)
      {
        if (ILI9341_checkButton(x, y, &bStart))
        {
          DeviceState = RUNNING;
          max30102_clear_fifo(&MAX30102);
          isButtonChange = true;
          isDeviceStateChange = true;
          memset(HRDataPlot, '\0', sizeof(HRDataPlot));
          memset(StepDataPlot, '\0', sizeof(StepDataPlot));
          HRDataIndex = 0;
          StepDataIndex = 0;
        }
      }
      else if (DeviceState == RUNNING)
      {
        if (ILI9341_checkButton(x, y, &bPause))
        {
          DeviceState = PAUSE;
          isButtonChange = true;
          isDeviceStateChange = true;
        }
        else if (ILI9341_checkButton(x, y, &bStop))
        {
          DeviceState = STOP;
          isButtonChange = true;
          isDeviceStateChange = true;
        }
      }
      else
      {
        if (ILI9341_checkButton(x, y, &bPause))
        {
          DeviceState = RUNNING;
          max30102_clear_fifo(&MAX30102);
          isButtonChange = true;
          isDeviceStateChange = true;
        }
        else if (ILI9341_checkButton(x, y, &bStop))
        {
          DeviceState = STOP;
          isButtonChange = true;
          isDeviceStateChange = true;
        }
      }
      break;
    }
    case MP3_PAGE:
    {
      if (ILI9341_checkButton(x, y, &toPageLeft))
      {
        CurrentPage = DATA_PAGE_2;
      }
      else if (ILI9341_checkButton(x, y, &toPageRight))
      {
        CurrentPage = MAIN_PAGE;
      }
      else if (ILI9341_checkButton(x, y, &bPlay))
      {
        isMP3Playing = !isMP3Playing;
        if (isMP3Playing == true)
        {DF_Playback();}
        else
        {DF_Pause();}
        isButtonChange = true;
      }
      else if (ILI9341_checkButton(x, y, &bPrev))
      {
        DF_Previous();
        if (isMP3Playing == false)
        {isButtonChange = true;}
        isMP3Playing = true;
        if (DF_getCurrentSongNumber() != 1)
        {DF_setCurrentSongNumber(DF_getCurrentSongNumber()-1);}
        else
        {DF_setCurrentSongNumber(DF_getTotalSongs());}
      }
      else if (ILI9341_checkButton(x, y, &bNext))
      {
        DF_Next();
        if (isMP3Playing == false)
        {isButtonChange = true;}
        isMP3Playing = true;
        if (DF_getCurrentSongNumber() != DF_getTotalSongs())
        {DF_setCurrentSongNumber(DF_getCurrentSongNumber()+1);}
        else
        {DF_setCurrentSongNumber(1);}
      }
      else if (ILI9341_checkButton(x, y, &incVol))
      {
        if (MP3Volume < 9)
        {MP3Volume++;}
        DF_SetVol(MP3Volume);
      }
      else if (ILI9341_checkButton(x, y, &decVol))
      {
        if (MP3Volume > 0)
        {MP3Volume--;}
        DF_SetVol(MP3Volume);
      }
      break;
    }
    case DATA_PAGE_2:
    {
      if (ILI9341_checkButton(x, y, &toPageLeft))
      {
        CurrentPage = DATA_PAGE_1;
      }
      else if (ILI9341_checkButton(x, y, &toPageRight))
      {
        CurrentPage = MP3_PAGE;
      }
      break;
    }
    case DATA_PAGE_1:
    {
      if (ILI9341_checkButton(x, y, &toPageLeft))
      {
        CurrentPage = MAIN_PAGE;
      }
      else if (ILI9341_checkButton(x, y, &toPageRight))
      {
        CurrentPage = DATA_PAGE_2;
      }
      break;
    }
    default:
    {
      break;
    }
  }
}

void Main_page(void)
{
  //========================================== CLEAR ================================================

  // ILI9341_FillScreen(ILI9341_BLACK);
  ILI9341_FillRectangle(0, 25, 320, 240, ILI9341_BLACK);

  //========================================= HEADER ========================================================

  if ((MQTT_Status.SIM_ST == SIM_SIMCARD_OK) || (MQTT_Status.SIM_ST == SIM_GPRS_OK))
  {ILI9341_WriteString(45, 10, "OK ", Font_7x10, ILI9341_GREEN, ILI9341_BLACK);}
  else
  {ILI9341_WriteString(45, 10, "nOK", Font_7x10, ILI9341_RED, ILI9341_BLACK);}
  if (MQTT_Status.SIM_ST == SIM_GPRS_OK)
  {ILI9341_WriteString(122, 10, "OK ", Font_7x10, ILI9341_GREEN, ILI9341_BLACK);}
  else
  {ILI9341_WriteString(122, 10, "nOK", Font_7x10, ILI9341_RED, ILI9341_BLACK);}
  if ((MQTT_Status.MQTT_ST == MQTT_OK) && (MQTT_Status.SIM_ST == SIM_GPRS_OK))
  {ILI9341_WriteString(192, 10, "OK ", Font_7x10, ILI9341_GREEN, ILI9341_BLACK);}
  else
  {ILI9341_WriteString(192, 10, "nOK", Font_7x10, ILI9341_RED, ILI9341_BLACK);}

  intToStr(Batt.Perc_Batt, Batt.cBatt, 3);
  ILI9341_WriteString(288, 10, Batt.cBatt, Font_7x10, ILI9341_YELLOW, ILI9341_BLACK);
  ILI9341_WriteString(309, 10, "%", Font_7x10, ILI9341_WHITE, ILI9341_BLACK);

  //============================================ DATE TIME =========================================

  memset(DateFormat, '\0', sizeof(DateFormat));
  sprintf(DateFormat, "~~~ %02d/%02d/%4d ~~~", myRTC.Date.date, myRTC.Date.month, myRTC.Date.year+2000);
  ILI9341_WriteString(97, 30, DateFormat, Font_7x10, ILI9341_WHITE, ILI9341_BLACK);

  memset(TimeFormat, '\0', sizeof(TimeFormat));
  sprintf(TimeFormat, "%02d:%02d", myRTC.Time.hours, myRTC.Time.minutes);
  ILI9341_WriteString(133, 45, TimeFormat, Font_11x18, ILI9341_CYAN, ILI9341_BLACK);

  //============================================ PARAMETERs =========================================

  ILI9341_WriteString(25, 70, "Heart Rate", Font_11x18, ILI9341_RED, ILI9341_BLACK);
  memset(HRFormat, '\0', sizeof(HRFormat));
  sprintf(HRFormat, "%03d", HeartRate);
  ILI9341_WriteString(37, 95, HRFormat, Font_11x18, ILI9341_RED, ILI9341_BLACK);
  ILI9341_WriteString(70, 95, " BPM", Font_11x18, ILI9341_RED, ILI9341_BLACK);

  ILI9341_WriteString(218, 70, "Step", Font_11x18, ILI9341_ORANGE, ILI9341_BLACK);
  memset(StepFormat, '\0', sizeof(StepFormat));
  sprintf(StepFormat, "%06ld", Step);
  ILI9341_WriteString(177, 95, StepFormat, Font_11x18, ILI9341_ORANGE, ILI9341_BLACK);
  ILI9341_WriteString(243, 95, " steps", Font_11x18, ILI9341_ORANGE, ILI9341_BLACK);

  ILI9341_WriteString(36, 125, "Run Time", Font_11x18, ILI9341_PINK, ILI9341_BLACK);
  memset(TimeRunFormat, '\0', sizeof(TimeRunFormat));
  sprintf(TimeRunFormat, "%03d", TimeRun);
  ILI9341_WriteString(36, 150, TimeRunFormat, Font_11x18, ILI9341_PINK, ILI9341_BLACK);
  ILI9341_WriteString(69, 150, " mins", Font_11x18, ILI9341_PINK, ILI9341_BLACK);

  ILI9341_WriteString(179, 125, "Coordinates", Font_11x18, ILI9341_GREEN, ILI9341_BLACK);
  ILI9341_WriteString(187, 147, "Lat: ", Font_7x10, ILI9341_GREEN, ILI9341_BLACK);
  ILI9341_WriteString(229, 147, latData, Font_7x10, ILI9341_GREEN, ILI9341_BLACK);
  ILI9341_WriteString(187, 160, "Lon: ", Font_7x10, ILI9341_GREEN, ILI9341_BLACK);
  ILI9341_WriteString(222, 160, longData, Font_7x10, ILI9341_GREEN, ILI9341_BLACK);

  //======================================= BUTTONs ================================================

  ILI9341_FillRectangle(bPause.pos_x, bPause.pos_y, 140, 30, ILI9341_BLACK);

  if (DeviceState == STOP)
  {
    ILI9341_FillRectangle(bStart.pos_x, bStart.pos_y, bStart.shape_w, bStart.shape_h, bStart.color);
    ILI9341_WriteString(bStart.pos_x+3, bStart.pos_y+6, "START", Font_11x18, ILI9341_WHITE, bStart.color);
  }
  else if (DeviceState == RUNNING)
  {
    ILI9341_FillRectangle(bPause.pos_x, bPause.pos_y, bPause.shape_w, bPause.shape_h, bPause.color);
    ILI9341_WriteString(bPause.pos_x+3, bPause.pos_y+6, "PAUSE", Font_11x18, ILI9341_WHITE, bPause.color);
    ILI9341_FillRectangle(bStop.pos_x, bStop.pos_y, bStop.shape_w, bStop.shape_h, bStop.color);
    ILI9341_WriteString(bStop.pos_x+8, bStop.pos_y+6, "STOP", Font_11x18, ILI9341_WHITE, bStop.color);
  }
  else
  {
    ILI9341_FillRectangle(bPause.pos_x, bPause.pos_y, bPause.shape_w, bPause.shape_h, bPause.color);
    ILI9341_WriteString(bPause.pos_x+3, bPause.pos_y+6, "START", Font_11x18, ILI9341_WHITE, bPause.color);
    ILI9341_FillRectangle(bStop.pos_x, bStop.pos_y, bStop.shape_w, bStop.shape_h, bStop.color);
    ILI9341_WriteString(bStop.pos_x+8, bStop.pos_y+6, "STOP", Font_11x18, ILI9341_WHITE, bStop.color);
  }

  ILI9341_FillCircle(toPageLeft.pos_x, toPageLeft.pos_y, toPageLeft.shape_r, ILI9341_LIGHTBLUE);
  ILI9341_FillRectangle(toPageLeft.pos_x, toPageLeft.pos_y-10, 15, 20, ILI9341_WHITE);
  ILI9341_FillTriangle(toPageLeft.pos_x, toPageLeft.pos_y-15, toPageLeft.pos_x-20, toPageLeft.pos_y, toPageLeft.pos_x, toPageLeft.pos_y+15, ILI9341_WHITE);

  ILI9341_FillCircle(toPageRight.pos_x, toPageRight.pos_y, toPageRight.shape_r, ILI9341_LIGHTBLUE);
  ILI9341_FillRectangle(toPageRight.pos_x-15, toPageRight.pos_y-10, 15, 20, ILI9341_WHITE);
  ILI9341_FillTriangle(toPageRight.pos_x, toPageRight.pos_y-15, toPageRight.pos_x+20, toPageRight.pos_y, toPageRight.pos_x, toPageRight.pos_y+15, ILI9341_WHITE);

}

void Mp3_page(void)
{
  //========================================== CLEAR ================================================

  // ILI9341_FillScreen(ILI9341_BLACK);
  ILI9341_FillRectangle(0, 25, 320, 240, ILI9341_BLACK);

  //========================================= HEADER ========================================================

  if ((MQTT_Status.SIM_ST == SIM_SIMCARD_OK) || (MQTT_Status.SIM_ST == SIM_GPRS_OK))
  {ILI9341_WriteString(45, 10, "OK ", Font_7x10, ILI9341_GREEN, ILI9341_BLACK);}
  else
  {ILI9341_WriteString(45, 10, "nOK", Font_7x10, ILI9341_RED, ILI9341_BLACK);}
  if (MQTT_Status.SIM_ST == SIM_GPRS_OK)
  {ILI9341_WriteString(122, 10, "OK ", Font_7x10, ILI9341_GREEN, ILI9341_BLACK);}
  else
  {ILI9341_WriteString(122, 10, "nOK", Font_7x10, ILI9341_RED, ILI9341_BLACK);}
  if ((MQTT_Status.MQTT_ST == MQTT_OK) && (MQTT_Status.SIM_ST == SIM_GPRS_OK))
  {ILI9341_WriteString(192, 10, "OK ", Font_7x10, ILI9341_GREEN, ILI9341_BLACK);}
  else
  {ILI9341_WriteString(192, 10, "nOK", Font_7x10, ILI9341_RED, ILI9341_BLACK);}

  intToStr(Batt.Perc_Batt, Batt.cBatt, 3);
  ILI9341_WriteString(288, 10, Batt.cBatt, Font_7x10, ILI9341_YELLOW, ILI9341_BLACK);
  ILI9341_WriteString(309, 10, "%", Font_7x10, ILI9341_WHITE, ILI9341_BLACK);

  //=========================================== MP3 INTERFACE =================================================

  ILI9341_WriteString(200, 50, "VOLUME: ", Font_11x18, ILI9341_YELLOW, ILI9341_BLACK);
  char temp[5] = {0};
  intToStr0(MP3Volume, temp, 2);
  ILI9341_WriteString(288, 50, temp, Font_11x18, ILI9341_YELLOW, ILI9341_BLACK);

  ILI9341_WriteString(10, 50, "TRACK: ", Font_11x18, ILI9341_CYAN, ILI9341_BLACK);
  memset(temp, '\0', sizeof(temp));
  intToStr0(DF_getCurrentSongNumber(), temp, 4);
  ILI9341_WriteString(87, 50, temp, Font_11x18, ILI9341_CYAN, ILI9341_BLACK);
  ILI9341_WriteString(131, 50, "/", Font_11x18, ILI9341_CYAN, ILI9341_BLACK);
  memset(temp, '\0', sizeof(temp));
  intToStr0(DF_getTotalSongs(), temp, 4);
  ILI9341_WriteString(142, 50, temp, Font_11x18, ILI9341_CYAN, ILI9341_BLACK);

  ILI9341_FillCircle(bPlay.pos_x, bPlay.pos_y, bPlay.shape_r, bPlay.color);
  if (isMP3Playing == false)
  {ILI9341_FillTriangle(bPlay.pos_x+20, bPlay.pos_y, bPlay.pos_x-10, bPlay.pos_y+18, bPlay.pos_x-10, bPlay.pos_y-18, ILI9341_ORANGE);}
  else
  {
    ILI9341_FillRectangle(bPlay.pos_x-5-bPlay.shape_r+20, bPlay.pos_y-bPlay.shape_r/2, bPlay.shape_r-20, bPlay.shape_r, ILI9341_RED);
      ILI9341_FillRectangle(bPlay.pos_x+5, bPlay.pos_y-bPlay.shape_r/2, bPlay.shape_r-20, bPlay.shape_r, ILI9341_RED);
  }

  ILI9341_FillCircle(bPrev.pos_x, bPrev.pos_y, bPrev.shape_r, bPrev.color);
  ILI9341_FillTriangle(bPrev.pos_x-2, bPrev.pos_y-10, bPrev.pos_x-15, bPrev.pos_y, bPrev.pos_x-2, bPrev.pos_y+10, ILI9341_BLUE);
  ILI9341_FillTriangle(bPrev.pos_x+11, bPrev.pos_y-10, bPrev.pos_x-2, bPrev.pos_y, bPrev.pos_x+11, bPrev.pos_y+10, ILI9341_BLUE);

  ILI9341_FillCircle(bNext.pos_x, bNext.pos_y, bNext.shape_r, bNext.color);
  ILI9341_FillTriangle(bNext.pos_x-11, bNext.pos_y-10, bNext.pos_x+2, bNext.pos_y, bNext.pos_x-11, bNext.pos_y+10, ILI9341_BLUE);
  ILI9341_FillTriangle(bNext.pos_x+2, bNext.pos_y-10, bNext.pos_x+15, bNext.pos_y, bNext.pos_x+2, bNext.pos_y+10, ILI9341_BLUE);

  ILI9341_FillCircle(decVol.pos_x, decVol.pos_y, decVol.shape_r, decVol.color);
  ILI9341_WriteString(decVol.pos_x-5, decVol.pos_y-8, "-", Font_11x18, ILI9341_BLACK, decVol.color);
  ILI9341_FillCircle(incVol.pos_x, incVol.pos_y, incVol.shape_r, incVol.color);
  ILI9341_WriteString(incVol.pos_x-5, incVol.pos_y-7, "+", Font_11x18, ILI9341_BLACK, incVol.color);

  //========================================================= PAGE CHANGE =======================================================================

  ILI9341_FillCircle(toPageLeft.pos_x, toPageLeft.pos_y, toPageLeft.shape_r, ILI9341_LIGHTBLUE);
  ILI9341_FillRectangle(toPageLeft.pos_x, toPageLeft.pos_y-10, 15, 20, ILI9341_WHITE);
  ILI9341_FillTriangle(toPageLeft.pos_x, toPageLeft.pos_y-15, toPageLeft.pos_x-20, toPageLeft.pos_y, toPageLeft.pos_x, toPageLeft.pos_y+15, ILI9341_WHITE);

  ILI9341_FillCircle(toPageRight.pos_x, toPageRight.pos_y, toPageRight.shape_r, ILI9341_LIGHTBLUE);
  ILI9341_FillRectangle(toPageRight.pos_x-15, toPageRight.pos_y-10, 15, 20, ILI9341_WHITE);
  ILI9341_FillTriangle(toPageRight.pos_x, toPageRight.pos_y-15, toPageRight.pos_x+20, toPageRight.pos_y, toPageRight.pos_x, toPageRight.pos_y+15, ILI9341_WHITE);
}

void Graph_page_1(void)
{
  //========================================== CLEAR ================================================

  // ILI9341_FillScreen(ILI9341_BLACK);
  ILI9341_FillRectangle(0, 25, 320, 240, ILI9341_BLACK);

  //========================================= HEADER ========================================================

  if ((MQTT_Status.SIM_ST == SIM_SIMCARD_OK) || (MQTT_Status.SIM_ST == SIM_GPRS_OK))
  {ILI9341_WriteString(45, 10, "OK ", Font_7x10, ILI9341_GREEN, ILI9341_BLACK);}
  else
  {ILI9341_WriteString(45, 10, "nOK", Font_7x10, ILI9341_RED, ILI9341_BLACK);}
  if (MQTT_Status.SIM_ST == SIM_GPRS_OK)
  {ILI9341_WriteString(122, 10, "OK ", Font_7x10, ILI9341_GREEN, ILI9341_BLACK);}
  else
  {ILI9341_WriteString(122, 10, "nOK", Font_7x10, ILI9341_RED, ILI9341_BLACK);}
  if ((MQTT_Status.MQTT_ST == MQTT_OK) && (MQTT_Status.SIM_ST == SIM_GPRS_OK))
  {ILI9341_WriteString(192, 10, "OK ", Font_7x10, ILI9341_GREEN, ILI9341_BLACK);}
  else
  {ILI9341_WriteString(192, 10, "nOK", Font_7x10, ILI9341_RED, ILI9341_BLACK);}

  intToStr(Batt.Perc_Batt, Batt.cBatt, 3);
  ILI9341_WriteString(288, 10, Batt.cBatt, Font_7x10, ILI9341_YELLOW, ILI9341_BLACK);
  ILI9341_WriteString(309, 10, "%", Font_7x10, ILI9341_WHITE, ILI9341_BLACK);

  //=====================================================================================================

  ILI9341_PlotTimeGraph8(60, 150, 200, (uint8_t*)HRDataPlot, 80, 50, 1, 50, 90, 130, 0, 500, 1000, "s", "BPM", ILI9341_RED);

  ILI9341_WriteString(94, 200, "HR over Time", Font_11x18, ILI9341_RED, ILI9341_BLACK);

  //========================================================= PAGE CHANGE =======================================================================

  ILI9341_FillCircle(toPageLeft.pos_x, toPageLeft.pos_y, toPageLeft.shape_r, ILI9341_LIGHTBLUE);
  ILI9341_FillRectangle(toPageLeft.pos_x, toPageLeft.pos_y-10, 15, 20, ILI9341_WHITE);
  ILI9341_FillTriangle(toPageLeft.pos_x, toPageLeft.pos_y-15, toPageLeft.pos_x-20, toPageLeft.pos_y, toPageLeft.pos_x, toPageLeft.pos_y+15, ILI9341_WHITE);

  ILI9341_FillCircle(toPageRight.pos_x, toPageRight.pos_y, toPageRight.shape_r, ILI9341_LIGHTBLUE);
  ILI9341_FillRectangle(toPageRight.pos_x-15, toPageRight.pos_y-10, 15, 20, ILI9341_WHITE);
  ILI9341_FillTriangle(toPageRight.pos_x, toPageRight.pos_y-15, toPageRight.pos_x+20, toPageRight.pos_y, toPageRight.pos_x, toPageRight.pos_y+15, ILI9341_WHITE);

}

void Graph_page_2(void)
{
  //========================================== CLEAR ================================================

  // ILI9341_FillScreen(ILI9341_BLACK);
  ILI9341_FillRectangle(0, 25, 320, 240, ILI9341_BLACK);

  //========================================= HEADER ========================================================

  if ((MQTT_Status.SIM_ST == SIM_SIMCARD_OK) || (MQTT_Status.SIM_ST == SIM_GPRS_OK))
  {ILI9341_WriteString(45, 10, "OK ", Font_7x10, ILI9341_GREEN, ILI9341_BLACK);}
  else
  {ILI9341_WriteString(45, 10, "nOK", Font_7x10, ILI9341_RED, ILI9341_BLACK);}
  if (MQTT_Status.SIM_ST == SIM_GPRS_OK)
  {ILI9341_WriteString(122, 10, "OK ", Font_7x10, ILI9341_GREEN, ILI9341_BLACK);}
  else
  {ILI9341_WriteString(122, 10, "nOK", Font_7x10, ILI9341_RED, ILI9341_BLACK);}
  if ((MQTT_Status.MQTT_ST == MQTT_OK) && (MQTT_Status.SIM_ST == SIM_GPRS_OK))
  {ILI9341_WriteString(192, 10, "OK ", Font_7x10, ILI9341_GREEN, ILI9341_BLACK);}
  else
  {ILI9341_WriteString(192, 10, "nOK", Font_7x10, ILI9341_RED, ILI9341_BLACK);}

  intToStr(Batt.Perc_Batt, Batt.cBatt, 3);
  ILI9341_WriteString(288, 10, Batt.cBatt, Font_7x10, ILI9341_YELLOW, ILI9341_BLACK);
  ILI9341_WriteString(309, 10, "%", Font_7x10, ILI9341_WHITE, ILI9341_BLACK);

  //=====================================================================================================

  ILI9341_PlotTimeGraph32(60, 160, 200, (uint32_t*)StepDataPlot, 100, 0, 100, 0, 5000, 10000, 0, 500, 1000, "s", "Step", ILI9341_GREEN);

  ILI9341_WriteString(83, 200, "Step over Time", Font_11x18, ILI9341_GREEN, ILI9341_BLACK);

  //========================================================= PAGE CHANGE =======================================================================

  ILI9341_FillCircle(toPageLeft.pos_x, toPageLeft.pos_y, toPageLeft.shape_r, ILI9341_LIGHTBLUE);
  ILI9341_FillRectangle(toPageLeft.pos_x, toPageLeft.pos_y-10, 15, 20, ILI9341_WHITE);
  ILI9341_FillTriangle(toPageLeft.pos_x, toPageLeft.pos_y-15, toPageLeft.pos_x-20, toPageLeft.pos_y, toPageLeft.pos_x, toPageLeft.pos_y+15, ILI9341_WHITE);

  ILI9341_FillCircle(toPageRight.pos_x, toPageRight.pos_y, toPageRight.shape_r, ILI9341_LIGHTBLUE);
  ILI9341_FillRectangle(toPageRight.pos_x-15, toPageRight.pos_y-10, 15, 20, ILI9341_WHITE);
  ILI9341_FillTriangle(toPageRight.pos_x, toPageRight.pos_y-15, toPageRight.pos_x+20, toPageRight.pos_y, toPageRight.pos_x, toPageRight.pos_y+15, ILI9341_WHITE);

}

/**
 * @brief Function call for checking peak (positive and negative) for a buffer of angle (int8)
 *
 * @param buffer angle data
 * @param size size of buffer
 * @param bandWith number of sample need to check
 * @param minHeight minimum height to be consider a peak
 * @param numFlatPeak number of sample consider to be a same peak
 * @return true - peak detected /
 * @return false - no peak
 */
bool isPeak(int8_t* buffer, uint8_t size, uint8_t bandWith, int8_t minHeight, uint8_t numFlatPeak)
{
  bool result = true;
  if (((buffer[size-1-bandWith] - buffer[size-1-bandWith/2]) >= minHeight) && ((buffer[size-1] - buffer[size-1-bandWith/2]) >= minHeight))
  {
    /*  negative peak check \\\\\./////   */
    for (uint8_t i = 0; i < (bandWith/2 - numFlatPeak/2); i++)
    {
      if (buffer[size-1-bandWith+i] < buffer[size-1-bandWith+i+1] || (buffer[size-1-i] < buffer[size-1-i-1]))
      {
        result = false;
      }
    }
    return result;
  }
  else if (((buffer[size-1-bandWith/2] - buffer[size-1-bandWith]) >= minHeight) && ((buffer[size-1-bandWith/2] - buffer[size-1]) >= minHeight))
  {
    /*  positive peak check /////.\\\\\   */
    for (uint8_t i = 0; i < (bandWith/2 - numFlatPeak/2); i++)
    {
      if (buffer[size-1-bandWith+i] > buffer[size-1-bandWith+i+1] || (buffer[size-1-i] > buffer[size-1-i-1]))
      {
        result = false;
      }
    }
    return result;
  }
  return false;
}

/* USER CODE END Application */
